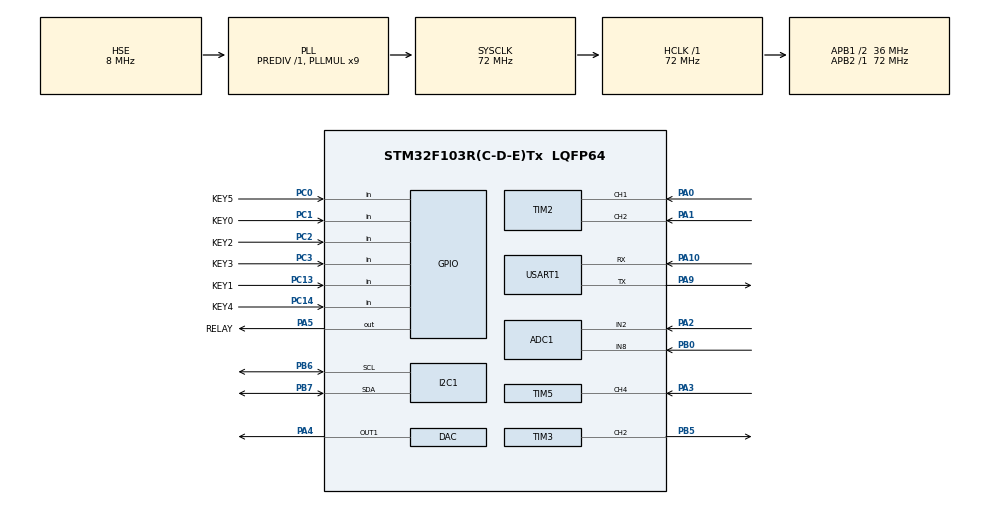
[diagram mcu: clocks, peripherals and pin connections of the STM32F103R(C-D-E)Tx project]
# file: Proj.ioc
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ADC1.Channel-2\#ChannelRegularConversion=ADC_CHANNEL_2
ADC1.Channel-3\#ChannelRegularConversion=ADC_CHANNEL_2
ADC1.ContinuousConvMode=ENABLE
ADC1.EnableRegularConversion=ENABLE
ADC1.ExternalTrigConv=ADC_SOFTWARE_START
ADC1.NbrOfConversion=2
ADC1.NbrOfConversionFlag=1
ADC1.Rank-2\#ChannelRegularConversion=1
ADC1.Rank-3\#ChannelRegularConversion=2
ADC1.SamplingTime-2\#ChannelRegularConversion=ADC_SAMPLETIME_1CYCLE_5
ADC1.SamplingTime-3\#ChannelRegularConversion=ADC_SAMPLETIME_1CYCLE_5
ADC1.master=1
Dma.ADC1.1.Direction=DMA_PERIPH_TO_MEMORY
Dma.ADC1.1.Instance=DMA1_Channel1
Dma.ADC1.1.MemDataAlignment=DMA_MDATAALIGN_HALFWORD
Dma.ADC1.1.MemInc=DMA_MINC_ENABLE
Dma.ADC1.1.Mode=DMA_CIRCULAR
Dma.ADC1.1.PeriphDataAlignment=DMA_PDATAALIGN_HALFWORD
Dma.ADC1.1.PeriphInc=DMA_PINC_DISABLE
Dma.ADC1.1.Priority=DMA_PRIORITY_HIGH
Dma.DAC_CH1.2.Direction=DMA_MEMORY_TO_PERIPH
Dma.DAC_CH1.2.Instance=DMA2_Channel3
Dma.DAC_CH1.2.MemDataAlignment=DMA_MDATAALIGN_HALFWORD
Dma.DAC_CH1.2.MemInc=DMA_MINC_ENABLE
Dma.DAC_CH1.2.Mode=DMA_CIRCULAR
Dma.DAC_CH1.2.PeriphDataAlignment=DMA_PDATAALIGN_HALFWORD
Dma.DAC_CH1.2.PeriphInc=DMA_PINC_DISABLE
Dma.DAC_CH1.2.Priority=DMA_PRIORITY_HIGH
Dma.I2C1_RX.4.Direction=DMA_PERIPH_TO_MEMORY
Dma.I2C1_RX.4.Instance=DMA1_Channel7
Dma.I2C1_RX.4.MemDataAlignment=DMA_MDATAALIGN_BYTE
Dma.I2C1_RX.4.MemInc=DMA_MINC_ENABLE
Dma.I2C1_RX.4.Mode=DMA_NORMAL
Dma.I2C1_RX.4.PeriphDataAlignment=DMA_PDATAALIGN_BYTE
Dma.I2C1_RX.4.PeriphInc=DMA_PINC_DISABLE
Dma.I2C1_RX.4.Priority=DMA_PRIORITY_LOW
Dma.I2C1_TX.3.Direction=DMA_MEMORY_TO_PERIPH
Dma.I2C1_TX.3.Instance=DMA1_Channel6
Dma.I2C1_TX.3.MemDataAlignment=DMA_MDATAALIGN_BYTE
Dma.I2C1_TX.3.MemInc=DMA_MINC_ENABLE
Dma.I2C1_TX.3.Mode=DMA_NORMAL
Dma.I2C1_TX.3.PeriphDataAlignment=DMA_PDATAALIGN_BYTE
Dma.I2C1_TX.3.PeriphInc=DMA_PINC_DISABLE
Dma.I2C1_TX.3.Priority=DMA_PRIORITY_LOW
Dma.Request0=USART1_TX
Dma.Request1=ADC1
Dma.Request2=DAC_CH1
Dma.Request3=I2C1_TX
Dma.Request4=I2C1_RX
Dma.USART1_TX.0.Direction=DMA_MEMORY_TO_PERIPH
Dma.USART1_TX.0.Instance=DMA1_Channel4
Dma.USART1_TX.0.MemDataAlignment=DMA_MDATAALIGN_BYTE
Dma.USART1_TX.0.MemInc=DMA_MINC_ENABLE
Dma.USART1_TX.0.Mode=DMA_NORMAL
Dma.USART1_TX.0.PeriphDataAlignment=DMA_PDATAALIGN_BYTE
Dma.USART1_TX.0.PeriphInc=DMA_PINC_DISABLE
Dma.USART1_TX.0.Priority=DMA_PRIORITY_LOW
FREERTOS.Tasks01=defaultTask,24,128,StartDefaultTask,Default,NULL,Dynamic,NULL,NULL
FREERTOS.configTOTAL_HEAP_SIZE=15360
Mcu.Family=STM32F1
Mcu.Name=STM32F103R(C-D-E)Tx
Mcu.Package=LQFP64
NVIC.DMA1_Channel1_IRQn=true\:5\:0\:false\:false\:true\:true\:false\:true\:true
NVIC.DMA1_Channel4_IRQn=true\:5\:0\:false\:false\:true\:true\:false\:true\:true
NVIC.DMA1_Channel6_IRQn=true\:5\:0\:false\:false\:true\:true\:false\:true\:true
NVIC.DMA1_Channel7_IRQn=true\:5\:0\:false\:false\:true\:true\:false\:true\:true
NVIC.DMA2_Channel3_IRQn=true\:5\:0\:false\:false\:true\:true\:false\:true\:true
NVIC.I2C1_ER_IRQn=true\:5\:0\:false\:false\:true\:true\:true\:true\:true
NVIC.I2C1_EV_IRQn=true\:5\:0\:false\:false\:true\:true\:true\:true\:true
NVIC.PriorityGroup=NVIC_PRIORITYGROUP_4
NVIC.TIM5_IRQn=true\:5\:0\:false\:false\:true\:true\:true\:true\:true
NVIC.TIM8_UP_IRQn=true\:15\:0\:false\:false\:true\:false\:false\:true\:true
NVIC.TimeBase=TIM8_UP_IRQn
NVIC.TimeBaseIP=TIM8
NVIC.USART1_IRQn=true\:5\:0\:false\:false\:true\:true\:false\:true\:true
PA0-WKUP.Signal=S_TIM2_CH1_ETR
PA1.Signal=S_TIM2_CH2
PA10.Mode=Asynchronous
PA10.Signal=USART1_RX
PA13.Mode=Serial_Wire
PA13.Signal=SYS_JTMS-SWDIO
PA14.Mode=Serial_Wire
PA14.Signal=SYS_JTCK-SWCLK
PA2.Signal=ADCx_IN2
PA3.GPIO_PuPd=GPIO_PULLDOWN
PA3.Signal=S_TIM5_CH4
PA4.Signal=COMP_DAC1_group
PA5.GPIO_Label=RELAY
PA5.Signal=GPIO_Output
PA9.Mode=Asynchronous
PA9.Signal=USART1_TX
PB0.Signal=ADCx_IN8
PB5.GPIO_Speed=GPIO_SPEED_FREQ_HIGH
PB5.Signal=S_TIM3_CH2
PB6.Mode=I2C
PB6.Signal=I2C1_SCL
PB7.Mode=I2C
PB7.Signal=I2C1_SDA
PC0.GPIO_Label=KEY5
PC0.Signal=GPIO_Input
PC1.GPIO_Label=KEY0
PC1.Signal=GPIO_Input
PC13-TAMPER-RTC.GPIO_Label=KEY1
PC13-TAMPER-RTC.Signal=GPIO_Input
PC14-OSC32_IN.GPIO_Label=KEY4
PC14-OSC32_IN.Signal=GPIO_Input
PC2.GPIO_Label=KEY2
PC2.Signal=GPIO_Input
PC3.GPIO_Label=KEY3
PC3.Signal=GPIO_Input
PD0-OSC_IN.Mode=HSE-External-Oscillator
PD0-OSC_IN.Signal=RCC_OSC_IN
PD1-OSC_OUT.Mode=HSE-External-Oscillator
PD1-OSC_OUT.Signal=RCC_OSC_OUT
ProjectManager.HeapSize=0x200
ProjectManager.StackSize=0x400
ProjectManager.TargetToolchain=MDK-ARM V5.32
RCC.ADCPresc=RCC_ADCPCLK2_DIV6
RCC.AHBFreq_Value=72000000
RCC.APB1CLKDivider=RCC_HCLK_DIV2
RCC.APB1Freq_Value=36000000
RCC.APB1TimFreq_Value=72000000
RCC.APB2Freq_Value=72000000
RCC.APB2TimFreq_Value=72000000
RCC.HCLKFreq_Value=72000000
RCC.PLLMUL=RCC_PLL_MUL9
RCC.PLLSourceVirtual=RCC_PLLSOURCE_HSE
RCC.SYSCLKFreq_VALUE=72000000
RCC.SYSCLKSource=RCC_SYSCLKSOURCE_PLLCLK
RCC.USBFreq_Value=72000000
SH.ADCx_IN2.0=ADC1_IN2,IN2
SH.ADCx_IN8.0=ADC1_IN8,IN8
SH.COMP_DAC1_group.0=DAC_OUT1,DAC_OUT1
SH.S_TIM2_CH1_ETR.0=TIM2_CH1,Encoder_Interface
SH.S_TIM2_CH2.0=TIM2_CH2,Encoder_Interface
SH.S_TIM3_CH2.0=TIM3_CH2,PWM Generation2 CH2
SH.S_TIM5_CH4.0=TIM5_CH4,Input_Capture4_from_TI4
TIM2.AutoReloadPreload=TIM_AUTORELOAD_PRELOAD_DISABLE
TIM2.EncoderMode=TIM_ENCODERMODE_TI12
TIM3.Channel-PWM\ Generation2\ CH2=TIM_CHANNEL_2
TIM5.AutoReloadPreload=TIM_AUTORELOAD_PRELOAD_ENABLE
TIM5.Channel-Input_Capture4_from_TI4=TIM_CHANNEL_4
TIM5.Prescaler=71
USART1.VirtualMode=VM_ASYNC
VP_FREERTOS_VS_CMSIS_V2.Mode=CMSIS_V2
VP_SYS_VS_tim8.Mode=TIM8
board=custom

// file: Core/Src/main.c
/* USER CODE BEGIN Header */
/**
  ******************************************************************************
  * @file           : main.c
  * @brief          : Main program body
  ******************************************************************************
  * @attention
  *
  * Copyright (c) 2026 STMicroelectronics.
  * All rights reserved.
  *
  * This software is licensed under terms that can be found in the LICENSE file
  * in the root directory of this software component.
  * If no LICENSE file comes with this software, it is provided AS-IS.
  *
  ******************************************************************************
  */
/* USER CODE END Header */
#include "main.h"
#include "cmsis_os.h"
#include "adc.h"
#include "dac.h"
#include "dma.h"
#include "i2c.h"
#include "tim.h"
#include "usart.h"
#include "gpio.h"

/* USER CODE BEGIN Includes */
#include "usr_main.h"
/* USER CODE END Includes */

void SystemClock_Config(void);
void MX_FREERTOS_Init(void);

int main(void)
{

  /* MCU Configuration--------------------------------------------------------*/

  /* Reset of all peripherals, Initializes the Flash interface and the Systick. */
  HAL_Init();

  /* Configure the system clock */
  SystemClock_Config();

  /* Initialize all configured peripherals */
  MX_GPIO_Init();
  MX_DMA_Init();
  MX_USART1_UART_Init();
  MX_DAC_Init();
  MX_TIM2_Init();
  MX_TIM3_Init();
  MX_TIM5_Init();
  MX_ADC1_Init();
  MX_I2C1_Init();
  /* USER CODE BEGIN 2 */
  Usr_Main_Init();
  /* USER CODE END 2 */

  /* Init scheduler */
  osKernelInitialize();  /* Call init function for freertos objects (in cmsis_os2.c) */
  MX_FREERTOS_Init();

  /* Start scheduler */
  osKernelStart();

  /* We should never get here as control is now taken by the scheduler */

  /* Infinite loop */
  while (1)
  {

  }
}

void SystemClock_Config(void)
{
  RCC_OscInitTypeDef RCC_OscInitStruct = {0};
  RCC_ClkInitTypeDef RCC_ClkInitStruct = {0};
  RCC_PeriphCLKInitTypeDef PeriphClkInit = {0};

  /** Initializes the RCC Oscillators according to the specified parameters
  * in the RCC_OscInitTypeDef structure.
  */
  RCC_OscInitStruct.OscillatorType = RCC_OSCILLATORTYPE_LSI|RCC_OSCILLATORTYPE_HSE;
  RCC_OscInitStruct.HSEState = RCC_HSE_ON;
  RCC_OscInitStruct.HSEPredivValue = RCC_HSE_PREDIV_DIV1;
  RCC_OscInitStruct.HSIState = RCC_HSI_ON;
  RCC_OscInitStruct.LSIState = RCC_LSI_ON;
  RCC_OscInitStruct.PLL.PLLState = RCC_PLL_ON;
  RCC_OscInitStruct.PLL.PLLSource = RCC_PLLSOURCE_HSE;
  RCC_OscInitStruct.PLL.PLLMUL = RCC_PLL_MUL9;
  if (HAL_RCC_OscConfig(&RCC_OscInitStruct) != HAL_OK)
  {
    Error_Handler();
  }

  /** Initializes the CPU, AHB and APB buses clocks
  */
  RCC_ClkInitStruct.ClockType = RCC_CLOCKTYPE_HCLK|RCC_CLOCKTYPE_SYSCLK
                              |RCC_CLOCKTYPE_PCLK1|RCC_CLOCKTYPE_PCLK2;
  RCC_ClkInitStruct.SYSCLKSource = RCC_SYSCLKSOURCE_PLLCLK;
  RCC_ClkInitStruct.AHBCLKDivider = RCC_SYSCLK_DIV1;
  RCC_ClkInitStruct.APB1CLKDivider = RCC_HCLK_DIV2;
  RCC_ClkInitStruct.APB2CLKDivider = RCC_HCLK_DIV1;

  if (HAL_RCC_ClockConfig(&RCC_ClkInitStruct, FLASH_LATENCY_2) != HAL_OK)
  {
    Error_Handler();
  }
  PeriphClkInit.PeriphClockSelection = RCC_PERIPHCLK_ADC;
  PeriphClkInit.AdcClockSelection = RCC_ADCPCLK2_DIV6;
  if (HAL_RCCEx_PeriphCLKConfig(&PeriphClkInit) != HAL_OK)
  {
    Error_Handler();
  }
}

void HAL_TIM_PeriodElapsedCallback(TIM_HandleTypeDef *htim)
{
  if (htim->Instance == TIM8)
  {
    HAL_IncTick();
  }
}

void Error_Handler(void)
{
  __disable_irq();
  while (1)
  {
  }
}

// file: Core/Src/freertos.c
/* USER CODE BEGIN Header */
/**
  ******************************************************************************
  * File Name          : freertos.c
  * Description        : Code for freertos applications
  ******************************************************************************
  * @attention
  *
  * Copyright (c) 2026 STMicroelectronics.
  * All rights reserved.
  *
  * This software is licensed under terms that can be found in the LICENSE file
  * in the root directory of this software component.
  * If no LICENSE file comes with this software, it is provided AS-IS.
  *
  ******************************************************************************
  */
/* USER CODE END Header */

#include "FreeRTOS.h"
#include "task.h"
#include "main.h"
#include "cmsis_os.h"

/* USER CODE BEGIN Includes */
#include "usr_freertos.h"
/* USER CODE END Includes */

/* Definitions for defaultTask */
osThreadId_t defaultTaskHandle;
const osThreadAttr_t defaultTask_attributes = {
  .name = "defaultTask",
  .stack_size = 128 * 4,
  .priority = (osPriority_t) osPriorityNormal,
};

void StartDefaultTask(void *argument);

void MX_FREERTOS_Init(void); /* (MISRA C 2004 rule 8.1) */

void MX_FREERTOS_Init(void) {

  /* Create the thread(s) */
  /* creation of defaultTask */
  defaultTaskHandle = osThreadNew(StartDefaultTask, NULL, &defaultTask_attributes);

  /* USER CODE BEGIN RTOS_THREADS */
  /* add threads, ... */
  Usr_FreeRTOS_Init();
  /* USER CODE END RTOS_THREADS */

}

void StartDefaultTask(void *argument)
{
  for(;;)
  {
    osDelay(1);
  }
}
